# STM32H7P4 register map
File version: 2.0.0
CPU: CM7 r1p2, little endian, MPU, FPU, 4 interrupt priority bits
Registers are 32-bit, read-write, reset 0x0 unless marked. A register's access mark holds for its fields unless they carry their own. Offsets are from the block's base; [hi:lo] are bit positions; {n}, {i} and the like mark numbered series; 'fields as' and 'values as' point back to an identical list.

## HRTIM1 (part 7 of 7) — HRTIM register block
Base 0x42006000
Same registers: HRTIM2 0x42007000
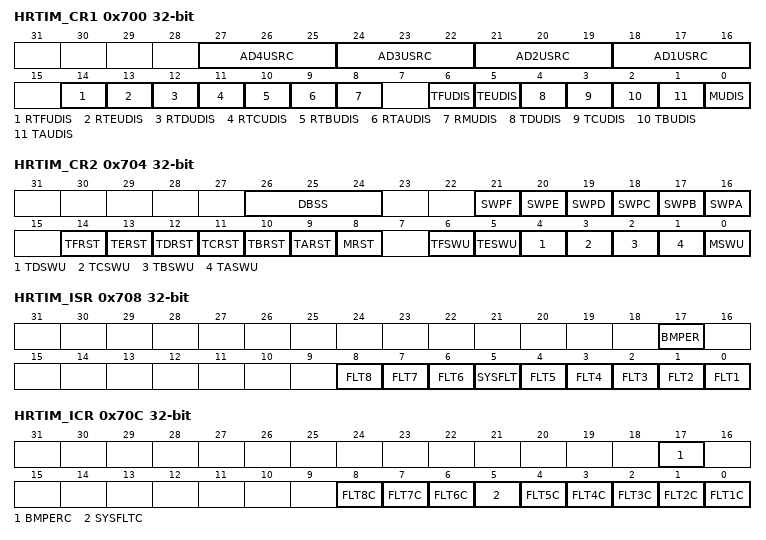
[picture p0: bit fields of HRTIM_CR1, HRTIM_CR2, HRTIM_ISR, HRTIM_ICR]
0x700 HRTIM_CR1 — HRTIM control register 1
  [27:25] AD4USRC — ADC trigger 4 update source
  [24:22] AD3USRC — ADC trigger 3 update source
  [21:19] AD2USRC — ADC trigger 2 update source
  [18:16] AD1USRC — ADC trigger 1 update source
    0=Master timer; 1=Timer A; 2=Timer B; 3=Timer C; 4=Timer D; 5=Timer E; 6=Timer F
  [14] RTFUDIS — Remote Timer F update disable
  [13] RTEUDIS — Remote Timer E update disable
  [12] RTDUDIS — Remote Timer D update disable
  [11] RTCUDIS — Remote Timer C update disable
  [10] RTBUDIS — Remote Timer B update disable
  [9] RTAUDIS — Remote timer A update disable
    0=Update enabled. The update occurs upon generation of the selected source.; 1=Update disabled. The updates are temporarily disabled to allow the software to write multiple registers that have to be simultaneously taken into account.
  [8] RMUDIS — Remote master update disable
    0=Update enabled; 1=Update disabled. The updates are temporarily disabled to allow the software to write multiple registers that have to be simultaneously taken into account.
  [6] TFUDIS — Timer F update disable
  [5] TEUDIS — Timer E update disable
  [4] TDUDIS — Timer D update disable
  [3] TCUDIS — Timer C update disable
  [2] TBUDIS — Timer B update disable
  [1] TAUDIS — Timer A update disable
    values as RTAUDIS
  [0] MUDIS — Master update disable
    values as RMUDIS
0x704 HRTIM_CR2 — HRTIM control register 2
  [26:24] DBSS — DMA burst source selection
    1=Master timer; 2=Timer A; 3=Timer B; 4=Timer C; 5=Timer D; 6=Timer E; 7=Timer F
  [21] SWPF — Swap timer F outputs
  [20] SWPE — Swap timer E outputs
  [19] SWPD — Swap timer D outputs
  [18] SWPC — Swap timer C outputs
  [17] SWPB — Swap timer B outputs
  [16] SWPA — Swap timer A outputs
    0=HRTIM_SETA1R and HRTIM_RSTA1R are coding for the output A1, HRTIM_SETA2R and HRTIM_RSTA2R are coding for the output A2; 1=HRTIM_SETA1R and HRTIM_RSTA1R are coding for the output A2, HRTIM_SETA2R and HRTIM_RSTA2R are coding for the output A1
  [14] TFRST — Timer F counter software reset
  [13] TERST — Timer E counter software reset
  [12] TDRST — Timer D counter software reset
  [11] TCRST — Timer C counter software reset
  [10] TBRST — Timer B counter software reset
  [9] TARST — Timer A counter software reset
  [8] MRST — Master counter software reset
  [6] TFSWU — Timer F software update
  [5] TESWU — Timer E software update
  [4] TDSWU — Timer D software update
  [3] TCSWU — Timer C software update
  [2] TBSWU — Timer B software update
  [1] TASWU — Timer A software update
  [0] MSWU — Master timer software update
0x708 HRTIM_ISR ro — HRTIM interrupt status register
  [17] BMPER — Burst mode period interrupt flag
    0=No burst mode period interrupt occurred; 1=Burst mode period interrupt occurred
  [8] FLT8 — Fault 8 interrupt flag
  [7] FLT7 — Fault 7 interrupt flag
  [6] FLT6 — Fault 6 interrupt flag
  [5] SYSFLT — System fault interrupt flag
  [n-1] FLT{n} (n=2..5) — Fault {n} interrupt flag
  [0] FLT1 — Fault 1 interrupt flag
    0=No fault 1 interrupt occurred; 1=Fault 1 interrupt occurred
0x70C HRTIM_ICR wo — HRTIM interrupt clear register
  [17] BMPERC — Burst mode period flag clear
  [8] FLT8C — Fault 8 interrupt flag clear
  [7] FLT7C — Fault 7 interrupt flag clear
  [6] FLT6C — Fault 6 interrupt flag clear
  [5] SYSFLTC — System fault interrupt flag clear
  [n-1] FLT{n}C (n=1..5) — Fault {n} interrupt flag clear
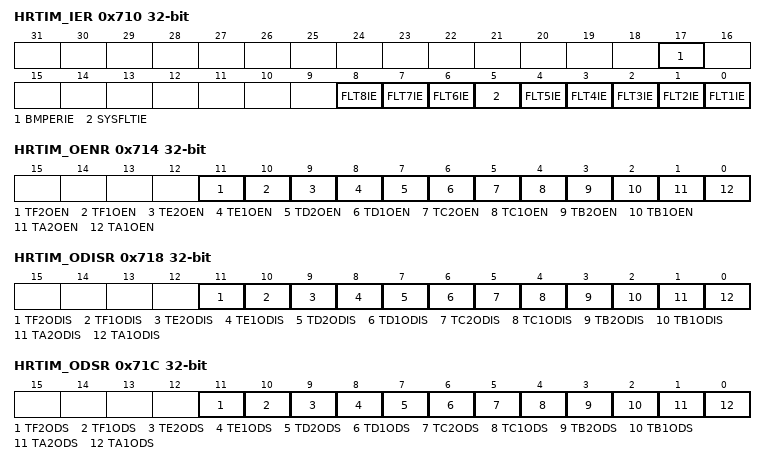
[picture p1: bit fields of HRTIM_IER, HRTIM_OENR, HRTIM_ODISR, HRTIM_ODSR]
0x710 HRTIM_IER — HRTIM interrupt enable register
  [17] BMPERIE — Burst mode period interrupt enable
    0=Burst mode period interrupt disabled; 1=Burst mode period interrupt enabled
  [8] FLT8IE — Fault 8 interrupt enable
  [7] FLT7IE — Fault 7 interrupt enable
  [6] FLT6IE — Fault 6 interrupt enable
  [5] SYSFLTIE — System fault interrupt enable
  [n-1] FLT{n}IE (n=2..5) — Fault {n} interrupt enable
  [0] FLT1IE — Fault 1 interrupt enable
    0=Fault 1 interrupt disabled; 1=Fault 1 interrupt enabled
0x714 HRTIM_OENR — HRTIM output enable register
  [11] TF2OEN — Timer F output 2 enable
  [10] TF1OEN — Timer F output 1 enable
  [9] TE2OEN — Timer E output 2 enable
  [8] TE1OEN — Timer E output 1 enable
  [7] TD2OEN — Timer D output 2 enable
  [6] TD1OEN — Timer D output 1 enable
  [5] TC2OEN — Timer C output 2 enable
  [4] TC1OEN — Timer C output 1 enable
  [3] TB2OEN — Timer B output 2 enable
  [2] TB1OEN — Timer B output 1 enable
  [1] TA2OEN — Timer A output 2 enable
  [0] TA1OEN — Timer A output 1 enable
    0=output A1 disabled. The output is either in fault or Idle state.; 1=output A1 enabled
0x718 HRTIM_ODISR wo — HRTIM output disable register
  [11] TF2ODIS — Timer F output 2 disable
  [10] TF1ODIS — Timer F output 1 disable
  [9] TE2ODIS — Timer E output 2 disable
  [8] TE1ODIS — Timer E output 1 disable
  [7] TD2ODIS — Timer D output 2 disable
  [6] TD1ODIS — Timer D output 1 disable
  [5] TC2ODIS — Timer C output 2 disable
  [4] TC1ODIS — Timer C output 1 disable
  [3] TB2ODIS — Timer B output 2 disable
  [2] TB1ODIS — Timer B output 1 disable
  [1] TA2ODIS — Timer A output 2 disable
  [0] TA1ODIS — Timer A output 1 disable
0x71C HRTIM_ODSR ro — HRTIM output disable status register
  [11] TF2ODS — Timer F output 2 disable status
  [10] TF1ODS — Timer F output 1 disable status
  [9] TE2ODS — Timer E output 2 disable status
  [8] TE1ODS — Timer E output 1 disable status
  [7] TD2ODS — Timer D output 2 disable status
  [6] TD1ODS — Timer D output 1 disable status
  [5] TC2ODS — Timer C output 2 disable status
  [4] TC1ODS — Timer C output 1 disable status
  [3] TB2ODS — Timer B output 2 disable status
  [2] TB1ODS — Timer B output 1 disable status
  [1] TA2ODS — Timer A output 2 disable status
  [0] TA1ODS — Timer A output 1 disable status
    0=Output A1 disabled, in Idle state; 1=Output A1 disabled, in fault state
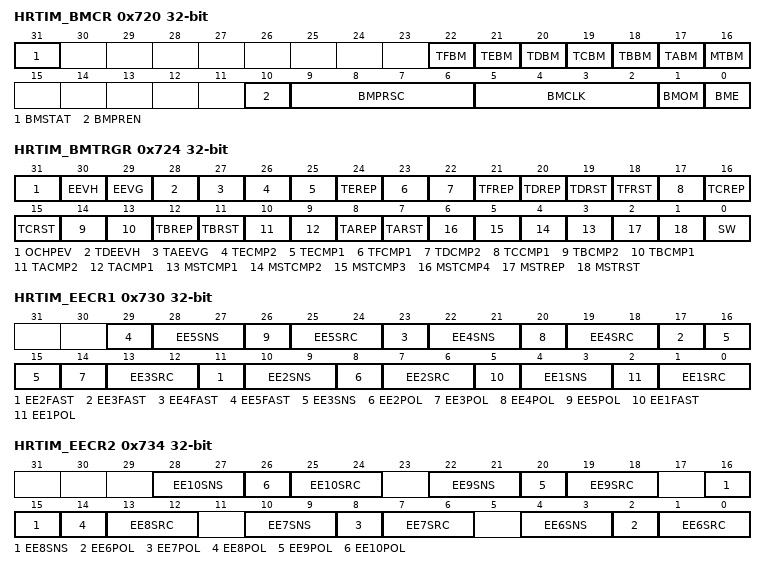
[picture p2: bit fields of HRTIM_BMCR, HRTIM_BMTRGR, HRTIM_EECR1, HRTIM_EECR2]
0x720 HRTIM_BMCR — HRTIM burst mode control register
  [31] BMSTAT — Burst mode status
    0=Normal operation; 1=Burst operation on-going. Writing this bit to 0 causes a burst mode early termination.
  [22] TFBM — Timer F burst mode
  [21] TEBM — Timer E burst mode
  [20] TDBM — Timer D burst mode
  [19] TCBM — Timer C burst mode
  [18] TBBM — Timer B burst mode
  [17] TABM — Timer A burst mode
    0=TA counter clock is maintained and the timer operates normally; 1=TA counter clock is stopped and the counter is reset
  [16] MTBM — Master timer burst mode
    0=Master Timer counter clock is maintained and the timer operates normally; 1=Master Timer counter clock is stopped and the counter is reset
  [10] BMPREN — Burst mode preload enable
    0=Preload disabled: the write access is directly done into active registers; 1=Preload enabled: the write access is done into preload registers
  [9:6] BMPRSC — Burst mode prescaler
    0=Clock not divided; 1=Division by 2; 2=Division by 4; 3=Division by 8; 4=Division by 16; 5=Division by 32; 6=Division by 64; 7=Division by 128; 8=Division by 256; 9=Division by 512; 10=Division by 1024; 11=Division by 2048; 12=Division by 4096; 13=Division by 8192; 14=Division by 16384; 15=Division by 32768
  [5:2] BMCLK — Burst mode clock source
    0=Master timer counter reset/roll-over; 1=Timer A counter reset/roll-over; 2=Timer B counter reset/roll-over; 3=Timer C counter reset/roll-over; 4=Timer D counter reset/roll-over; 5=Timer E counter reset/roll-over; 6=On-chip event 1 (hrtim_bm_ck1), acting as a burst mode counter clock; 7=On-chip event 2 (hrtim_bm_ck2) acting as a burst mode counter clock; 8=On-chip event 3 (hrtim_bm_ck3) acting as a burst mode counter clock; 9=On-chip event 4 (hrtim_bm_ck4) acting as a burst mode counter clock; 10=Prescaled fless thansub>HRTIMless than/sub> clock (as per BMPRSC[3:0] setting); 11=Timer F counter reset/roll-over
  [1] BMOM — Burst mode operating mode
    0=Single-shot mode; 1=Continuous operation
  [0] BME — Burst mode enable
    0=Burst mode disabled; 1=Burst mode enabled
0x724 HRTIM_BMTRGR — HRTIM burst mode trigger register
  [31] OCHPEV — On-chip event
  [30] EEVH — External event H (TIMD filters applied)
  [29] EEVG — External event G (TIMA filters applied)
  [28] TDEEVH — Timer D period following external event H
  [27] TAEEVG — Timer A period following external event G
  [26] TECMP2 — Timer E compare 2 event
  [25] TECMP1 — Timer E compare 1 event
  [24] TEREP — Timer E repetition
  [23] TFCMP1 — Timer F compare 1 event
  [22] TDCMP2 — Timer D compare 2 event
  [21] TFREP — Timer F repetition
  [20] TDREP — Timer D repetition
  [19] TDRST — Timer D reset or roll-over
  [18] TFRST — Timer F reset
  [17] TCCMP1 — Timer C compare 1 event
  [16] TCREP — Timer C repetition
  [15] TCRST — Timer C reset or roll-over
  [14] TBCMP2 — Timer B compare 2 event
  [13] TBCMP1 — Timer B compare 1 event
  [12] TBREP — Timer B repetition
  [11] TBRST — Timer B reset or roll-over
  [10] TACMP2 — Timer A compare 2 event
  [9] TACMP1 — Timer A compare 1 event
  [8] TAREP — Timer A repetition
  [7] TARST — Timer A reset or roll-over
  [n+2] MSTCMP{n} (n=1..4) — Master compare {n}
  [2] MSTREP — Master repetition
  [1] MSTRST — Master reset or roll-over
  [0] SW — Software start
0x728 HRTIM_BMCMPR — HRTIM burst mode compare register
  [15:0] BMCMP — Burst mode compare value
0x72C HRTIM_BMPER — HRTIM burst mode period register
  [15:0] BMPER — Burst mode period
0x730 HRTIM_EECR1 — HRTIM timer external event control register 1
  [6n-1] EE{n}FAST (n=2..5) — External event {n} fast mode
  [6n-2:6n-3] EE{n}SNS (n=2..5) — External event {n} sensitivity
  [6n-4] EE{n}POL (n=2..5) — External event {n} polarity
  [6n-5:6n-6] EE{n}SRC (n=2..5) — External event {n} source
  [5] EE1FAST — External event 1 fast mode
    0=External event 1 is re-synchronized by the HRTIM logic before acting on outputs, which adds a fless thansub>HRTIMless than/sub> clock-related latency; 1=External event 1 is acting asynchronously on outputs (low latency mode)
  [4:3] EE1SNS — External event 1 sensitivity
    0=On active level defined by EE1POL bit; 1=Rising edge, whatever EE1POL bit value; 2=Falling edge, whatever EE1POL bit value; 3=Both edges, whatever EE1POL bit value
  [2] EE1POL — External event 1 polarity
    0=External event is active high; 1=External event is active low
  [1:0] EE1SRC — External event 1 source
    0=hrtim_eev1_1; 1=hrtim_eev1_6; 2=hrtim_eev1_7; 3=hrtim_eev1_8
0x734 HRTIM_EECR2 — HRTIM timer external event control register 2
  [6n-32:6n-33] EE{n}SNS (n=6..10) — External event {n} sensitivity
  [6n-34] EE{n}POL (n=6..10) — External event {n} polarity
  [6n-35:6n-36] EE{n}SRC (n=6..10) — External event {n} source
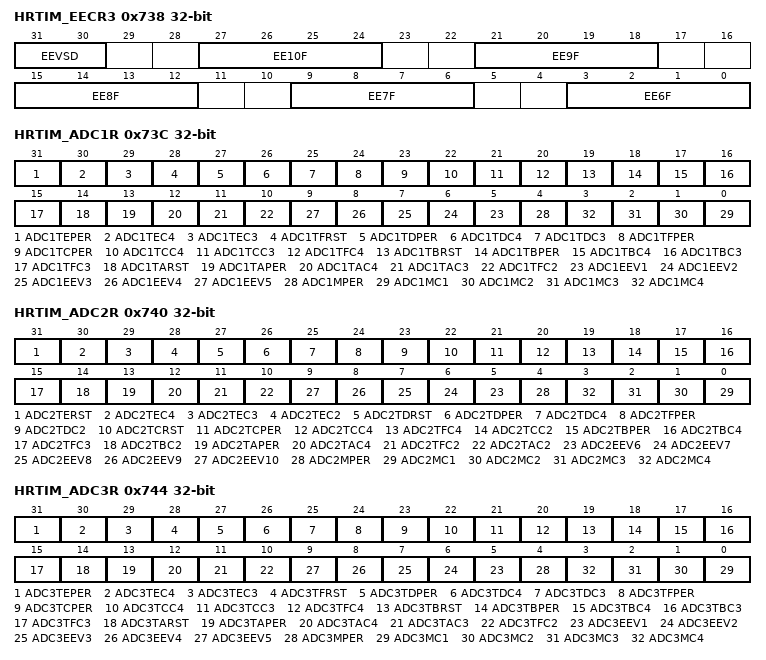
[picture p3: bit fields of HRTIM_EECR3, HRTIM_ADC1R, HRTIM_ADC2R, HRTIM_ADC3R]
0x738 HRTIM_EECR3 — HRTIM timer external event control register 3
  [31:30] EEVSD — External event sampling clock division
    0=fless thansub>EEVSless than/sub>=fless thansub>HRTIMless than/sub>; 1=fless thansub>EEVSless than/sub>=fless thansub>HRTIMless than/sub> / 2; 2=fless thansub>EEVSless than/sub>=fless thansub>HRTIMless than/sub> / 4; 3=fless thansub>EEVSless than/sub>=fless thansub>HRTIMless than/sub> / 8
  [6n-33:6n-36] EE{n}F (n=7..10) — External event {n} filter
  [3:0] EE6F — External event 6 filter
    0=Filter disabled; 1=fless thansub>SAMPLINGless than/sub>= fless thansub>HRTIMless than/sub>, N=2; 2=fless thansub>SAMPLINGless than/sub>= fless thansub>HRTIMless than/sub>, N=4; 3=fless thansub>SAMPLINGless than/sub>= fless thansub>HRTIMless than/sub>, N=8; 4=fless thansub>SAMPLINGless than/sub>= fless thansub>EEVSless than/sub>/2, N=6; 5=fless thansub>SAMPLINGless than/sub>= fless thansub>EEVSless than/sub>/2, N=8; 6=fless thansub>SAMPLINGless than/sub>= fless thansub>EEVSless than/sub>/4, N=6; 7=fless thansub>SAMPLINGless than/sub>= fless thansub>EEVSless than/sub>/4, N=8; 8=fless thansub>SAMPLINGless than/sub>= fless thansub>EEVSless than/sub>/8, N=6; 9=fless thansub>SAMPLINGless than/sub>= fless thansub>EEVSless than/sub>/8, N=8; 10=fless thansub>SAMPLINGless than/sub>= fless thansub>EEVSless than/sub>/16, N=5; 11=fless thansub>SAMPLINGless than/sub>= fless thansub>EEVSless than/sub>/16, N=6; 12=fless thansub>SAMPLINGless than/sub>= fless thansub>EEVSless than/sub>/16, N=8; 13=fless thansub>SAMPLINGless than/sub>= fless thansub>EEVSless than/sub>/32, N=5; 14=fless thansub>SAMPLINGless than/sub>= fless thansub>EEVSless than/sub>/32, N=6; 15=fless thansub>SAMPLINGless than/sub>= fless thansub>EEVSless than/sub>/32, N=8
0x73C HRTIM_ADC1R — HRTIM ADC trigger 1 register
  [31] ADC1TEPER — ADC trigger 1 on timer E period
  [30] ADC1TEC4 — ADC trigger 1 on timer E compare 4
  [29] ADC1TEC3 — ADC trigger 1 on timer E compare 3
  [28] ADC1TFRST — ADC trigger 1 on timer F reset and counter roll-over
  [27] ADC1TDPER — ADC trigger 1 on timer D period
  [26] ADC1TDC4 — ADC trigger 1 on timer D compare 4
  [25] ADC1TDC3 — ADC trigger 1 on timer D compare 3
  [24] ADC1TFPER — ADC trigger 1 on timer F period
  [23] ADC1TCPER — ADC trigger 1 on timer C period
  [22] ADC1TCC4 — ADC trigger 1 on timer C compare 4
  [21] ADC1TCC3 — ADC trigger 1 on timer C compare 3
  [20] ADC1TFC4 — ADC trigger 1 on timer F compare 4
  [19] ADC1TBRST — ADC trigger 1 on timer B reset and counter roll-overless thansup>(1)less than/sup>
  [18] ADC1TBPER — ADC trigger 1 on timer B period
  [17] ADC1TBC4 — ADC trigger 1 on timer B compare 4
  [16] ADC1TBC3 — ADC trigger 1 on timer B compare 3
  [15] ADC1TFC3 — ADC trigger 1 on timer F compare 3
  [14] ADC1TARST — ADC trigger 1 on timer A reset and counter roll-overless thansup>(1)less than/sup>
  [13] ADC1TAPER — ADC trigger 1 on timer A period
  [12] ADC1TAC4 — ADC trigger 1 on timer A compare 4
  [11] ADC1TAC3 — ADC trigger 1 on timer A compare 3
  [10] ADC1TFC2 — ADC trigger 1 on timer F compare 2
  [n+4] ADC1EEV{n} (n=1..5) — ADC trigger 1 on external event {n}less thansup>(1)less than/sup>
  [4] ADC1MPER — ADC trigger 1 on master period
  [n-1] ADC1MC{n} (n=1..4) — ADC trigger 1 on master compare {n}
0x740 HRTIM_ADC2R — HRTIM ADC trigger 2 register
  [31] ADC2TERST — ADC trigger 2 on timer E reset and counter roll-over
  [30] ADC2TEC4 — ADC trigger 2 on timer E compare 4
  [29] ADC2TEC3 — ADC trigger 2 on timer E compare 3
  [28] ADC2TEC2 — ADC trigger 2 on timer E compare 2
  [27] ADC2TDRST — ADC trigger 2 on timer D reset and counter roll-overless thansup>(1)less than/sup>
  [26] ADC2TDPER — ADC trigger 2 on timer D period
  [25] ADC2TDC4 — ADC trigger 2 on timer D compare 4
  [24] ADC2TFPER — ADC trigger 2 on timer F period
  [23] ADC2TDC2 — ADC trigger 2 on timer D compare 2
  [22] ADC2TCRST — ADC trigger 2 on timer C reset and counter roll-overless thansup>(1)less than/sup>
  [21] ADC2TCPER — ADC trigger 2 on timer C period
  [20] ADC2TCC4 — ADC trigger 2 on timer C compare 4
  [19] ADC2TFC4 — ADC trigger 2 on timer F compare 4
  [18] ADC2TCC2 — ADC trigger 2 on timer C compare 2
  [17] ADC2TBPER — ADC trigger 2 on timer B period
  [16] ADC2TBC4 — ADC trigger 2 on timer B compare 4
  [15] ADC2TFC3 — ADC trigger 2 on timer F compare 3
  [14] ADC2TBC2 — ADC trigger 2 on timer B compare 2
  [13] ADC2TAPER — ADC trigger 2 on timer A period
  [12] ADC2TAC4 — ADC trigger 2 on timer A compare 4
  [11] ADC2TFC2 — ADC trigger 2 on timer F compare 2
  [10] ADC2TAC2 — ADC trigger 2 on timer A compare 2
  [n-1] ADC2EEV{n} (n=6..10) — ADC trigger 2 on external event {n}less thansup>(1)less than/sup>
  [4] ADC2MPER — ADC trigger 2 on master period
  [n-1] ADC2MC{n} (n=1..4) — ADC trigger 2 on master compare {n}
0x744 HRTIM_ADC3R — HRTIM ADC trigger 3 register
  [31] ADC3TEPER — ADC trigger 3 on timer E period
  [30] ADC3TEC4 — ADC trigger 3 on timer E compare 4
  [29] ADC3TEC3 — ADC trigger 3 on timer E compare 3
  [28] ADC3TFRST — ADC trigger 3 on timer F reset and counter roll-over
  [27] ADC3TDPER — ADC trigger 3 on timer D period
  [26] ADC3TDC4 — ADC trigger 3 on timer D compare 4
  [25] ADC3TDC3 — ADC trigger 3 on timer D compare 3
  [24] ADC3TFPER — ADC trigger 3 on timer F period
  [23] ADC3TCPER — ADC trigger 3 on timer C period
  [22] ADC3TCC4 — ADC trigger 3 on timer C compare 4
  [21] ADC3TCC3 — ADC trigger 3 on timer C compare 3
  [20] ADC3TFC4 — ADC trigger 3 on timer F compare 4
  [19] ADC3TBRST — ADC trigger 3 on timer B reset and counter roll-overless thansup>(1)less than/sup>
  [18] ADC3TBPER — ADC trigger 3 on timer B period
  [17] ADC3TBC4 — ADC trigger 3 on timer B compare 4
  [16] ADC3TBC3 — ADC trigger 3 on timer B compare 3
  [15] ADC3TFC3 — ADC trigger 3 on timer F compare 3
  [14] ADC3TARST — ADC trigger 3 on timer A reset and counter roll-overless thansup>(1)less than/sup>
  [13] ADC3TAPER — ADC trigger 3 on timer A period
  [12] ADC3TAC4 — ADC trigger 3 on timer A compare 4
  [11] ADC3TAC3 — ADC trigger 3 on timer A compare 3
  [10] ADC3TFC2 — ADC trigger 3 on timer F compare 2
  [n+4] ADC3EEV{n} (n=1..5) — ADC trigger 3 on external event {n}less thansup>(1)less than/sup>
  [4] ADC3MPER — ADC trigger 3 on master period
  [n-1] ADC3MC{n} (n=1..4) — ADC trigger 3 on master compare {n}
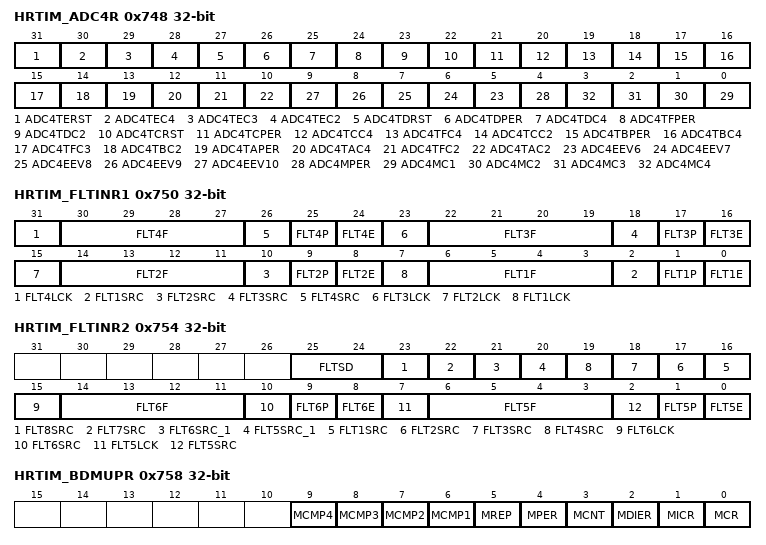
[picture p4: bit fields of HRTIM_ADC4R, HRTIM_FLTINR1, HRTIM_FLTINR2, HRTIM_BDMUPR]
0x748 HRTIM_ADC4R — HRTIM ADC trigger 4 register
  [31] ADC4TERST — ADC trigger 4 on timer E reset and counter roll-over
  [30] ADC4TEC4 — ADC trigger 4 on timer E compare 4
  [29] ADC4TEC3 — ADC trigger 4 on timer E compare 3
  [28] ADC4TEC2 — ADC trigger 4 on timer E compare 2
  [27] ADC4TDRST — ADC trigger 4 on timer D reset and counter roll-overless thansup>(1)less than/sup>
  [26] ADC4TDPER — ADC trigger 4 on timer D period
  [25] ADC4TDC4 — ADC trigger 4 on timer D compare 4
  [24] ADC4TFPER — ADC trigger 4 on timer F period
  [23] ADC4TDC2 — ADC trigger 2 on timer D compare 2
  [22] ADC4TCRST — ADC trigger 4 on timer C reset and counter roll-overless thansup>(1)less than/sup>
  [21] ADC4TCPER — ADC trigger 4 on timer C period
  [20] ADC4TCC4 — ADC trigger 4 on timer C compare 4
  [19] ADC4TFC4 — ADC trigger 4 on timer F compare 4
  [18] ADC4TCC2 — ADC trigger 4 on timer C compare 2
  [17] ADC4TBPER — ADC trigger 4 on timer B period
  [16] ADC4TBC4 — ADC trigger 4 on timer B compare 4
  [15] ADC4TFC3 — ADC trigger 4 on timer F compare 3
  [14] ADC4TBC2 — ADC trigger 4 on timer B compare 2
  [13] ADC4TAPER — ADC trigger 4 on timer A period
  [12] ADC4TAC4 — ADC trigger 4 on timer A compare 4
  [11] ADC4TFC2 — ADC trigger 4 on timer F compare 2
  [10] ADC4TAC2 — ADC trigger 4 on timer A compare 2
  [n-1] ADC4EEV{n} (n=6..10) — ADC trigger 4 on external event {n}less thansup>(1)less than/sup>
  [4] ADC4MPER — ADC trigger 4 on master period
  [n-1] ADC4MC{n} (n=1..4) — ADC trigger 4 on master compare {n}
0x750 HRTIM_FLTINR1 rw-once — HRTIM fault input register 1
  [31] FLT4LCK — Fault 4 lock
  [8n-2:8n-5] FLT{n}F rw (n=1..4) — Fault {n} filter
  [8n-6] FLT{n}SRC rw (n=1..4) — Fault {n} source bit 0
  [8n-7] FLT{n}P rw (n=1..4) — Fault {n} polarity
  [8n-8] FLT{n}E rw (n=1..4) — Fault {n} enable
  [23] FLT3LCK rw — Fault 3 lock
  [15] FLT2LCK — Fault 2 lock
  [7] FLT1LCK rw — Fault 1 lock
0x754 HRTIM_FLTINR2 rw-once — HRTIM fault input register 2
  [25:24] FLTSD rw — Fault sampling clock division
    0=fless thansub>FLTSless than/sub>=fless thansub>HRTIMless than/sub>; 1=fless thansub>FLTSless than/sub>=fless thansub>HRTIMless than/sub> / 2; 2=fless thansub>FLTSless than/sub>=fless thansub>HRTIMless than/sub> / 4; 3=fless thansub>FLTSless than/sub>=fless thansub>HRTIMless than/sub> / 8
  [23] FLT8SRC rw — Fault 8 source bit 1
  [22] FLT7SRC rw — Fault 7 source bit 1
  [21] FLT6SRC_1 rw
  [20] FLT5SRC_1 rw
  [n+15] FLT{n}SRC rw (n=1..4) — Fault {n} source bit 1
  [15] FLT6LCK — Fault 6 lock
  [14:11] FLT6F rw — Fault 6 filter
  [10] FLT6SRC rw — FLT6SRC[0]: Fault 6 source bit 0
  [9] FLT6P rw — Fault 6 polarity
  [8] FLT6E rw — Fault 6 enable
  [7] FLT5LCK — Fault 5 lock
    0=FLT5E, FLT5P, FLT5SRC[1:0], FLT5F[3:0] and FLT5BLK bits are read/write; 1=FLT5E, FLT5P, FLT5SRC[1:0], FLT5F[3:0] and FLT5BLK bits cannot be written (read-only mode)
  [6:3] FLT5F rw — Fault 5 filter
    0=No filter, FLT5 acts asynchronously; 1=fless thansub>SAMPLINGless than/sub>= fless thansub>HRTIMless than/sub>, N = 2; 2=fless thansub>SAMPLINGless than/sub> = fless thansub>HRTIMless than/sub>, N = 4; 3=fless thansub>SAMPLINGless than/sub> = fless thansub>HRTIMless than/sub>, N = 8; 4=fless thansub>SAMPLINGless than/sub> = fless thansub>FLTSless than/sub>/2, N = 6; 5=fless thansub>SAMPLINGless than/sub> = fless thansub>FLTSless than/sub>/2, N = 8; 6=fless thansub>SAMPLINGless than/sub> = fless thansub>FLTSless than/sub>/4, N = 6; 7=fless thansub>SAMPLINGless than/sub> = fless thansub>FLTSless than/sub>/4, N = 8; 8=fless thansub>SAMPLINGless than/sub> = fless thansub>FLTSless than/sub>/8, N = 6; 9=fless thansub>SAMPLINGless than/sub> = fless thansub>FLTSless than/sub>/8, N = 8; 10=fless thansub>SAMPLINGless than/sub> = fless thansub>FLTSless than/sub>/16, N = 5; 11=fless thansub>SAMPLINGless than/sub> = fless thansub>FLTSless than/sub>/16, N = 6; 12=fless thansub>SAMPLINGless than/sub> = fless thansub>FLTSless than/sub>/16, N = 8; 13=fless thansub>SAMPLINGless than/sub> = fless thansub>FLTSless than/sub>/32, N = 5; 14=fless thansub>SAMPLINGless than/sub> = fless thansub>FLTSless than/sub>/32, N = 6; 15=fless thansub>SAMPLINGless than/sub> = fless thansub>FLTSless than/sub>/32, N = 8
  [2] FLT5SRC rw — FLT5SRC[0]: Fault 5 source bit 0
    0=Fault 5 input is HRTIM_FLT5 input pin; 1=Fault 5 input is connected to a COMPx output
  [1] FLT5P rw — Fault 5 polarity
    0=Fault 5 input is active low; 1=Fault 5 input is active high
  [0] FLT5E rw — Fault 5 enable
    0=Fault 5 input disabled; 1=Fault 5 input enabled
0x758 HRTIM_BDMUPR — HRTIM burst DMA master timer update register
  [n+5] MCMP{n} (n=1..4) — MCMP{n}R register update enable
  [5] MREP — MREP register update enable
  [4] MPER — MPER register update enable
  [3] MCNT — MCNTR register update enable
  [2] MDIER — MDIER register update enable
  [1] MICR — MICR register update enable
  [0] MCR — MCR register update enable
    0=MCR register is not updated by burst DMA accesses; 1=MCR register is updated by burst DMA accesses
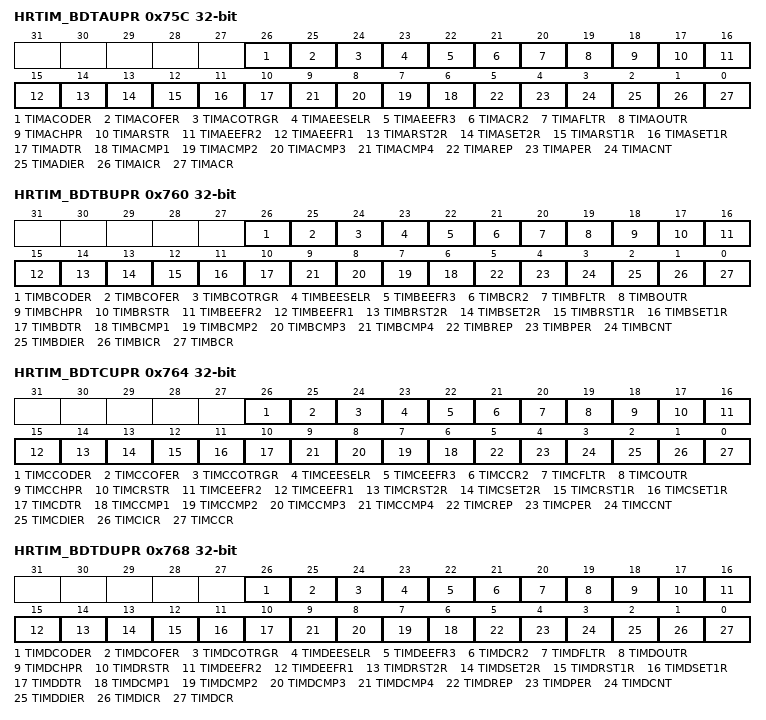
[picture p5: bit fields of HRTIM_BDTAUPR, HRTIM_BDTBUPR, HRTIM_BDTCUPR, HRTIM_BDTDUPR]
0x75C HRTIM_BDTAUPR — HRTIM burst DMA timer A update register
  [26] TIMACODER — HRTIM_CODExR register update enable timer x
  [25] TIMACOFER — HRTIM_COFExR register update enable timer x
  [24] TIMACOTRGR — HRTIM_COTRGxR register update enable timer x
  [23] TIMAEESELR — HRTIM_EESELxR register update enable timer x
  [22] TIMAEEFR3 — HRTIM_EEFxR3 register update enable timer x
  [21] TIMACR2 — HRTIM_TIMxCR2 register update enable timer x
  [20] TIMAFLTR — HRTIM_FLTxR register update enable timer x
  [19] TIMAOUTR — HRTIM_OUTxR register update enable timer x
  [18] TIMACHPR — HRTIM_CHPxR register update enable timer x
  [17] TIMARSTR — HRTIM_RSTxR register update enable timer x
  [16] TIMAEEFR2 — HRTIM_EEFxR2 register update enable timer x
  [15] TIMAEEFR1 — HRTIM_EEFxR1 register update enable timer x
  [14] TIMARST2R — HRTIM_RST2xR register update enable timer x
  [13] TIMASET2R — HRTIM_SET2xR register update enable timer x
  [12] TIMARST1R — HRTIM_RST1xR register update enable timer x
  [11] TIMASET1R — HRTIM_SET1xR register update enable timer x
  [10] TIMADTR — HRTIM_DTxR register update enable timer x
  [n+5] TIMACMP{n} (n=1..4) — HRTIM_CMP{n}xR register update enable timer x
  [5] TIMAREP — HRTIM_REPxR register update enable timer x
  [4] TIMAPER — HRTIM_PERxR register update enable timer x
  [3] TIMACNT — HRTIM_CNTxR register update enable timer x
  [2] TIMADIER — HRTIM_TIMxDIER register update enable timer x
  [1] TIMAICR — HRTIM_TIMxICR register update enable timer x
  [0] TIMACR — HRTIM_TIMxCR register update enable timer x
    0=HRTIM_TIMxCR register is not updated by burst DMA accesses; 1=HRTIM_TIMxCR register is updated by burst DMA accesses
0x760 HRTIM_BDTBUPR — HRTIM burst DMA timer B update register
  [26] TIMBCODER — HRTIM_CODExR register update enable timer x
  [25] TIMBCOFER — HRTIM_COFExR register update enable timer x
  [24] TIMBCOTRGR — HRTIM_COTRGxR register update enable timer x
  [23] TIMBEESELR — HRTIM_EESELxR register update enable timer x
  [22] TIMBEEFR3 — HRTIM_EEFxR3 register update enable timer x
  [21] TIMBCR2 — HRTIM_TIMxCR2 register update enable timer x
  [20] TIMBFLTR — HRTIM_FLTxR register update enable timer x
  [19] TIMBOUTR — HRTIM_OUTxR register update enable timer x
  [18] TIMBCHPR — HRTIM_CHPxR register update enable timer x
  [17] TIMBRSTR — HRTIM_RSTxR register update enable timer x
  [16] TIMBEEFR2 — HRTIM_EEFxR2 register update enable timer x
  [15] TIMBEEFR1 — HRTIM_EEFxR1 register update enable timer x
  [14] TIMBRST2R — HRTIM_RST2xR register update enable timer x
  [13] TIMBSET2R — HRTIM_SET2xR register update enable timer x
  [12] TIMBRST1R — HRTIM_RST1xR register update enable timer x
  [11] TIMBSET1R — HRTIM_SET1xR register update enable timer x
  [10] TIMBDTR — HRTIM_DTxR register update enable timer x
  [n+5] TIMBCMP{n} (n=1..4) — HRTIM_CMP{n}xR register update enable timer x
  [5] TIMBREP — HRTIM_REPxR register update enable timer x
  [4] TIMBPER — HRTIM_PERxR register update enable timer x
  [3] TIMBCNT — HRTIM_CNTxR register update enable timer x
  [2] TIMBDIER — HRTIM_TIMxDIER register update enable timer x
  [1] TIMBICR — HRTIM_TIMxICR register update enable timer x
  [0] TIMBCR — HRTIM_TIMxCR register update enable timer x
    values as HRTIM_BDTAUPR.TIMACR
0x764 HRTIM_BDTCUPR — HRTIM burst DMA timer C update register
  [26] TIMCCODER — HRTIM_CODExR register update enable timer x
  [25] TIMCCOFER — HRTIM_COFExR register update enable timer x
  [24] TIMCCOTRGR — HRTIM_COTRGxR register update enable timer x
  [23] TIMCEESELR — HRTIM_EESELxR register update enable timer x
  [22] TIMCEEFR3 — HRTIM_EEFxR3 register update enable timer x
  [21] TIMCCR2 — HRTIM_TIMxCR2 register update enable timer x
  [20] TIMCFLTR — HRTIM_FLTxR register update enable timer x
  [19] TIMCOUTR — HRTIM_OUTxR register update enable timer x
  [18] TIMCCHPR — HRTIM_CHPxR register update enable timer x
  [17] TIMCRSTR — HRTIM_RSTxR register update enable timer x
  [16] TIMCEEFR2 — HRTIM_EEFxR2 register update enable timer x
  [15] TIMCEEFR1 — HRTIM_EEFxR1 register update enable timer x
  [14] TIMCRST2R — HRTIM_RST2xR register update enable timer x
  [13] TIMCSET2R — HRTIM_SET2xR register update enable timer x
  [12] TIMCRST1R — HRTIM_RST1xR register update enable timer x
  [11] TIMCSET1R — HRTIM_SET1xR register update enable timer x
  [10] TIMCDTR — HRTIM_DTxR register update enable timer x
  [n+5] TIMCCMP{n} (n=1..4) — HRTIM_CMP{n}xR register update enable timer x
  [5] TIMCREP — HRTIM_REPxR register update enable timer x
  [4] TIMCPER — HRTIM_PERxR register update enable timer x
  [3] TIMCCNT — HRTIM_CNTxR register update enable timer x
  [2] TIMCDIER — HRTIM_TIMxDIER register update enable timer x
  [1] TIMCICR — HRTIM_TIMxICR register update enable timer x
  [0] TIMCCR — HRTIM_TIMxCR register update enable timer x
    values as HRTIM_BDTAUPR.TIMACR
0x768 HRTIM_BDTDUPR — HRTIM burst DMA timer D update register
  [26] TIMDCODER — HRTIM_CODExR register update enable timer x
  [25] TIMDCOFER — HRTIM_COFExR register update enable timer x
  [24] TIMDCOTRGR — HRTIM_COTRGxR register update enable timer x
  [23] TIMDEESELR — HRTIM_EESELxR register update enable timer x
  [22] TIMDEEFR3 — HRTIM_EEFxR3 register update enable timer x
  [21] TIMDCR2 — HRTIM_TIMxCR2 register update enable timer x
  [20] TIMDFLTR — HRTIM_FLTxR register update enable timer x
  [19] TIMDOUTR — HRTIM_OUTxR register update enable timer x
  [18] TIMDCHPR — HRTIM_CHPxR register update enable timer x
  [17] TIMDRSTR — HRTIM_RSTxR register update enable timer x
  [16] TIMDEEFR2 — HRTIM_EEFxR2 register update enable timer x
  [15] TIMDEEFR1 — HRTIM_EEFxR1 register update enable timer x
  [14] TIMDRST2R — HRTIM_RST2xR register update enable timer x
  [13] TIMDSET2R — HRTIM_SET2xR register update enable timer x
  [12] TIMDRST1R — HRTIM_RST1xR register update enable timer x
  [11] TIMDSET1R — HRTIM_SET1xR register update enable timer x
  [10] TIMDDTR — HRTIM_DTxR register update enable timer x
  [n+5] TIMDCMP{n} (n=1..4) — HRTIM_CMP{n}xR register update enable timer x
  [5] TIMDREP — HRTIM_REPxR register update enable timer x
  [4] TIMDPER — HRTIM_PERxR register update enable timer x
  [3] TIMDCNT — HRTIM_CNTxR register update enable timer x
  [2] TIMDDIER — HRTIM_TIMxDIER register update enable timer x
  [1] TIMDICR — HRTIM_TIMxICR register update enable timer x
  [0] TIMDCR — HRTIM_TIMxCR register update enable timer x
    values as HRTIM_BDTAUPR.TIMACR
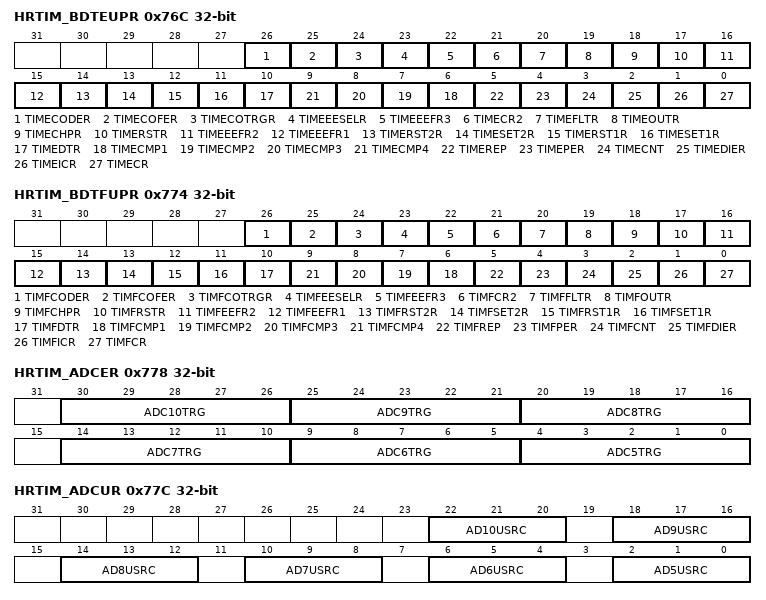
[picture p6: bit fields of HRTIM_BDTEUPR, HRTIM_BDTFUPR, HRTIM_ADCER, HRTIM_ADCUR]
0x76C HRTIM_BDTEUPR — HRTIM burst DMA timer E update register
  [26] TIMECODER — HRTIM_CODExR register update enable timer x
  [25] TIMECOFER — HRTIM_COFExR register update enable timer x
  [24] TIMECOTRGR — HRTIM_COTRGxR register update enable timer x
  [23] TIMEEESELR — HRTIM_EESELxR register update enable timer x
  [22] TIMEEEFR3 — HRTIM_EEFxR3 register update enable timer x
  [21] TIMECR2 — HRTIM_TIMxCR2 register update enable timer x
  [20] TIMEFLTR — HRTIM_FLTxR register update enable timer x
  [19] TIMEOUTR — HRTIM_OUTxR register update enable timer x
  [18] TIMECHPR — HRTIM_CHPxR register update enable timer x
  [17] TIMERSTR — HRTIM_RSTxR register update enable timer x
  [16] TIMEEEFR2 — HRTIM_EEFxR2 register update enable timer x
  [15] TIMEEEFR1 — HRTIM_EEFxR1 register update enable timer x
  [14] TIMERST2R — HRTIM_RST2xR register update enable timer x
  [13] TIMESET2R — HRTIM_SET2xR register update enable timer x
  [12] TIMERST1R — HRTIM_RST1xR register update enable timer x
  [11] TIMESET1R — HRTIM_SET1xR register update enable timer x
  [10] TIMEDTR — HRTIM_DTxR register update enable timer x
  [n+5] TIMECMP{n} (n=1..4) — HRTIM_CMP{n}xR register update enable timer x
  [5] TIMEREP — HRTIM_REPxR register update enable timer x
  [4] TIMEPER — HRTIM_PERxR register update enable timer x
  [3] TIMECNT — HRTIM_CNTxR register update enable timer x
  [2] TIMEDIER — HRTIM_TIMxDIER register update enable timer x
  [1] TIMEICR — HRTIM_TIMxICR register update enable timer x
  [0] TIMECR — HRTIM_TIMxCR register update enable timer x
    values as HRTIM_BDTAUPR.TIMACR
0x770 HRTIM_BDMADR wo — HRTIM burst DMA data register
  [31:0] BDMADR — Burst DMA data register
0x774 HRTIM_BDTFUPR — HRTIM burst DMA timer F update register
  [26] TIMFCODER — HRTIM_CODExR register update enable timer x
  [25] TIMFCOFER — HRTIM_COFExR register update enable timer x
  [24] TIMFCOTRGR — HRTIM_COTRGxR register update enable timer x
  [23] TIMFEESELR — HRTIM_EESELxR register update enable timer x
  [22] TIMFEEFR3 — HRTIM_EEFxR3 register update enable timer x
  [21] TIMFCR2 — HRTIM_TIMxCR2 register update enable timer x
  [20] TIMFFLTR — HRTIM_FLTxR register update enable timer x
  [19] TIMFOUTR — HRTIM_OUTxR register update enable timer x
  [18] TIMFCHPR — HRTIM_CHPxR register update enable timer x
  [17] TIMFRSTR — HRTIM_RSTxR register update enable timer x
  [16] TIMFEEFR2 — HRTIM_EEFxR2 register update enable timer x
  [15] TIMFEEFR1 — HRTIM_EEFxR1 register update enable timer x
  [14] TIMFRST2R — HRTIM_RST2xR register update enable timer x
  [13] TIMFSET2R — HRTIM_SET2xR register update enable timer x
  [12] TIMFRST1R — HRTIM_RST1xR register update enable timer x
  [11] TIMFSET1R — HRTIM_SET1xR register update enable timer x
  [10] TIMFDTR — HRTIM_DTxR register update enable timer x
  [n+5] TIMFCMP{n} (n=1..4) — HRTIM_CMP{n}xR register update enable timer x
  [5] TIMFREP — HRTIM_REPxR register update enable timer x
  [4] TIMFPER — HRTIM_PERxR register update enable timer x
  [3] TIMFCNT — HRTIM_CNTxR register update enable timer x
  [2] TIMFDIER — HRTIM_TIMxDIER register update enable timer x
  [1] TIMFICR — HRTIM_TIMxICR register update enable timer x
  [0] TIMFCR — HRTIM_TIMxCR register update enable timer x
    values as HRTIM_BDTAUPR.TIMACR
0x778 HRTIM_ADCER — HRTIM ADC extended trigger register
  [30:26] ADC10TRG — ADC trigger 10 selection
  [25:21] ADC9TRG — ADC trigger 9 selection
  [20:16] ADC8TRG — ADC trigger 8 selection
  [14:10] ADC7TRG — ADC trigger 7 selection
  [9:5] ADC6TRG — ADC trigger 6 selection
    0=Trigger on master compare 1; 1=Trigger on master compare 2; 2=Trigger on timer A compare 2; 3=Trigger on timer A compare 4
  [4:0] ADC5TRG — ADC trigger 5 selection
    0=Trigger on master compare 1; 1=Trigger on master compare 2; 2=Trigger on timer A compare 3; 3=Trigger on timer A compare 4
0x77C HRTIM_ADCUR — HRTIM ADC trigger update register
  [4n-18:4n-20] AD{n}USRC (n=6..10) — ADC trigger {n} update source
  [2:0] AD5USRC — ADC trigger 5 update source
    values as HRTIM_CR1.AD1USRC
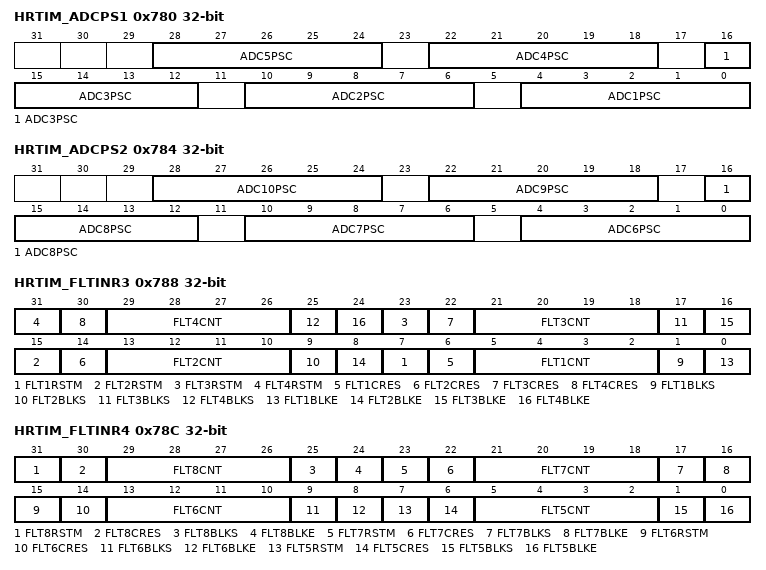
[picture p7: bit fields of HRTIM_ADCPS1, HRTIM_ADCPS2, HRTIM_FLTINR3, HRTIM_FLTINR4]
0x780 HRTIM_ADCPS1 — HRTIM ADC post scaler register 1
  [6n-2:6n-6] ADC{n}PSC (n=1..5) — ADC {n} post scaler
0x784 HRTIM_ADCPS2 — HRTIM ADC post scaler register 2
  [6n-32:6n-36] ADC{n}PSC (n=6..10) — ADC {n} post scaler
0x788 HRTIM_FLTINR3 — HRTIM fault input register 3
  [8n-1] FLT{n}RSTM (n=1..4) — Fault {n} reset mode
  [8n-2] FLT{n}CRES (n=1..4) — Fault {n} counter reset
  [8n-3:8n-6] FLT{n}CNT (n=1..4) — Fault {n} counter
  [8n-7] FLT{n}BLKS (n=1..4) — Fault {n} blanking source
  [8n-8] FLT{n}BLKE (n=1..4) — Fault {n} blanking enable
0x78C HRTIM_FLTINR4 — HRTIM fault input register 4
  [31] FLT8RSTM — Fault 8 reset mode
  [30] FLT8CRES — Fault 8 counter reset
  [8n-35:8n-38] FLT{n}CNT (n=5..8) — Fault {n} counter
  [25] FLT8BLKS — Fault 8 blanking source
  [24] FLT8BLKE — Fault 8 blanking enable
  [23] FLT7RSTM — Fault 7 reset mode
  [22] FLT7CRES — Fault 7 counter reset
  [17] FLT7BLKS — Fault 7 blanking source
  [16] FLT7BLKE — Fault 7 blanking enable
  [15] FLT6RSTM — Fault 6 reset mode
  [14] FLT6CRES — Fault 6 counter reset
  [9] FLT6BLKS — Fault 6 blanking source
  [8] FLT6BLKE — Fault 6 blanking enable
  [7] FLT5RSTM — Fault 5 reset mode
    0=Fault 5 counter is reset on each reset / roll-over event; 1=Fault 5 counter is reset on each reset / roll-over event only if no fault occurred during last counting period
  [6] FLT5CRES — Fault 5 counter reset
    0=No action; 1=Fault 5 counter is reset
  [1] FLT5BLKS — Fault 5 blanking source
    0=Fault 5 reset-aligned blanking window; 1=Fault 5 Moving blanking window
  [0] FLT5BLKE — Fault 5 blanking enable
    0=No blanking on fault 5; 1=Fault 5 blanking mode
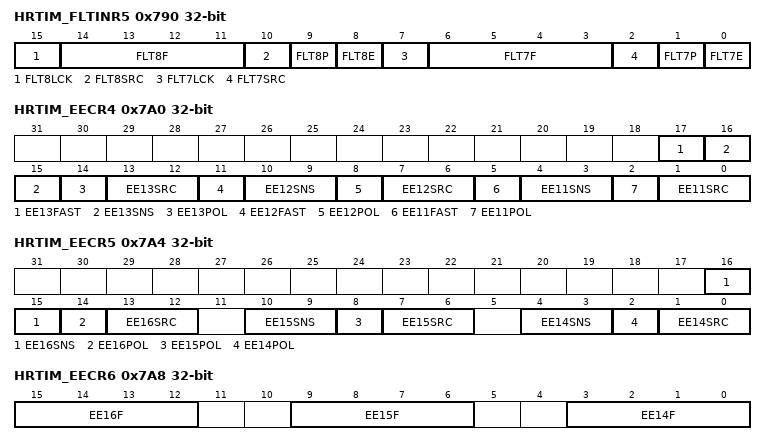
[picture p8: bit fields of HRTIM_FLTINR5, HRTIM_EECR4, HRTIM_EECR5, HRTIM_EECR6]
0x790 HRTIM_FLTINR5 rw-once — HRTIM fault input register 5
  [15] FLT8LCK — Fault 8 lock
  [14:11] FLT8F rw — Fault 8 filter
  [10] FLT8SRC rw — Fault 8 source bit 0
  [9] FLT8P rw — Fault 8 polarity
  [8] FLT8E rw — Fault 8 enable
  [7] FLT7LCK — Fault 7 lock
    0=FLT7E, FLT7P, FLT7SRC[1:0], FLT7F[3:0] and FLT7BLK bits are read/write; 1=FLT7E, FLT7P, FLT7SRC[1:0], FLT7F[3:0] and FLT7BLK bits cannot be written (read-only mode)
  [6:3] FLT7F rw — Fault 7 filter
    0=No filter, FLT7 acts asynchronously; 1=fless thansub>SAMPLINGless than/sub>= fless thansub>HRTIMless than/sub>, N = 2; 2=fless thansub>SAMPLINGless than/sub> = fless thansub>HRTIMless than/sub>, N = 4; 3=fless thansub>SAMPLINGless than/sub> = fless thansub>HRTIMless than/sub>, N = 8; 4=fless thansub>SAMPLINGless than/sub> = fless thansub>FLTSless than/sub>/2, N = 6; 5=fless thansub>SAMPLINGless than/sub> = fless thansub>FLTSless than/sub>/2, N = 8; 6=fless thansub>SAMPLINGless than/sub> = fless thansub>FLTSless than/sub>/4, N = 6; 7=fless thansub>SAMPLINGless than/sub> = fless thansub>FLTSless than/sub>/4, N = 8; 8=fless thansub>SAMPLINGless than/sub> = fless thansub>FLTSless than/sub>/8, N = 6; 9=fless thansub>SAMPLINGless than/sub> = fless thansub>FLTSless than/sub>/8, N = 8; 10=fless thansub>SAMPLINGless than/sub> = fless thansub>FLTSless than/sub>/16, N = 5; 11=fless thansub>SAMPLINGless than/sub> = fless thansub>FLTSless than/sub>/16, N = 6; 12=fless thansub>SAMPLINGless than/sub> = fless thansub>FLTSless than/sub>/16, N = 8; 13=fless thansub>SAMPLINGless than/sub> = fless thansub>FLTSless than/sub>/32, N = 5; 14=fless thansub>SAMPLINGless than/sub> = fless thansub>FLTSless than/sub>/32, N = 6; 15=fless thansub>SAMPLINGless than/sub> = fless thansub>FLTSless than/sub>/32, N = 8
  [2] FLT7SRC rw — Fault 7 source bit 0
    0=Fault 7 input is HRTIM_FLT7 input pin; 1=ext_trg7
  [1] FLT7P rw — Fault 7 polarity
    0=Fault 7 input is active low; 1=Fault 7 input is active high
  [0] FLT7E rw — Fault 7 enable
    0=Fault 7 input disabled; 1=Fault 7 input enabled
0x7A0 HRTIM_EECR4 — HRTIM timer external event control register 4
  [17] EE13FAST — External event 3 fast mode
  [16:15] EE13SNS — External event 3 sensitivity
  [14] EE13POL — External event 3 polarity
  [13:12] EE13SRC — External event 3 source
  [11] EE12FAST — External event 2 fast mode
  [10:9] EE12SNS — External event 2 sensitivity
  [8] EE12POL — External event 2 polarity
  [7:6] EE12SRC — External event 2 source
  [5] EE11FAST — External event 11 fast mode
    0=External event 11 is re-synchronized by the HRTIM logic before acting on outputs, which adds a fless thansub>HRTIMless than/sub> clock-related latency; 1=External event 11 is acting asynchronously on outputs (low latency mode)
  [4:3] EE11SNS — External event 11 sensitivity
    0=On active level defined by EE11POL bit; 1=Rising edge, whatever EE11POL bit value; 2=Falling edge, whatever EE11POL bit value; 3=Both edges, whatever EE11POL bit value
  [2] EE11POL — External event 11 polarity
    values as HRTIM_EECR1.EE1POL
  [1:0] EE11SRC — External event 11 source
    {v}=hrtim_eev11_{v+1} (v=0..3)
0x7A4 HRTIM_EECR5 — HRTIM timer external event control register 5
  [16:15] EE16SNS — External event 16 sensitivity
  [14] EE16POL — External event 16 polarity
  [13:12] EE16SRC — External event 16 source
  [10:9] EE15SNS — External event 15 sensitivity
  [8] EE15POL — External event 15 polarity
  [7:6] EE15SRC — External event 15 source
  [4:3] EE14SNS — External event 14 sensitivity
    0=On active level defined by EE14POL bit; 1=Rising edge, whatever EE14POL bit value; 2=Falling edge, whatever EE14POL bit value; 3=Both edges, whatever EE14POL bit value
  [2] EE14POL — External event 14 polarity
    values as HRTIM_EECR1.EE1POL
  [1:0] EE14SRC — External event 14 source
    {v}=hrtim_eev14_{v+1} (v=0..3)
0x7A8 HRTIM_EECR6 — HRTIM timer external event control register 6
  [15:12] EE16F — External event 16 filter
  [9:6] EE15F — External event 15 filter
  [3:0] EE14F — External event 14 filter
    values as HRTIM_EECR3.EE6F
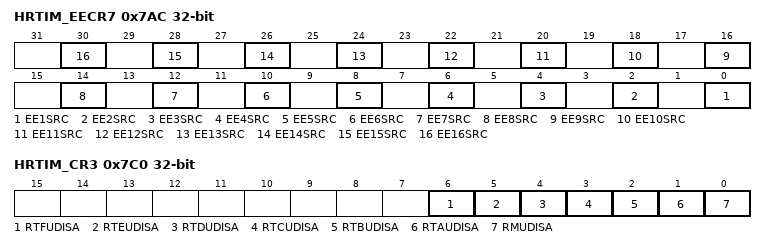
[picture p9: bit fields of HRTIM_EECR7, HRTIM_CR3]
0x7AC HRTIM_EECR7 — HRTIM timer external event control register 7
  [2n-2] EE{n}SRC (n=1..16) — External event {n} source - bit 2
0x7C0 HRTIM_CR3 — HRTIM control register 3
  [6] RTFUDISA — Remote timer F update disable authorization
  [5] RTEUDISA — Remote timer E update disable authorization
  [4] RTDUDISA — Remote timer D update disable authorization
  [3] RTCUDISA — Remote timer C update disable authorization
  [2] RTBUDISA — Remote timer B update disable authorization
  [1] RTAUDISA — Remote timer A update disable authorization
    0=Remote update disable requests are ignored; 1=Remote update disable requests authorized
  [0] RMUDISA — Remote master update disable authorization
    values as RTAUDISA
0x7FC HRTIM_OR — HRTIM option register
  [0] HSPBKSEL — HSP break selection
    0=B_0x0_HRTIM1 (hsp_break_out0 disabled); 1=B_0x1_HRTIM1 (hsp_break_out0 enabled and connected to hrtim1_sys_flt)
